# RP2350 register map
Vendor: Raspberry Pi; Series: RP; File version: 0.1
CPU: CM33 r1p0, little endian, MPU, FPU, DSP, VTOR, 4 interrupt priority bits, 52 interrupts, 8 SAU regions
Registers are 32-bit, read-write, reset 0x0 unless marked. A register's access mark holds for its fields unless they carry their own. Offsets are from the block's base; [hi:lo] are bit positions; {n}, {i} and the like mark numbered series.

## CORESIGHT_TRACE — Coresight block - RP specific registers
Base 0x50700000
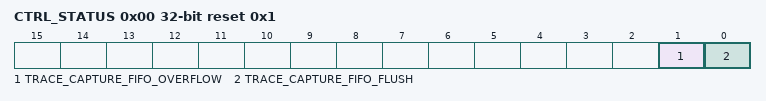
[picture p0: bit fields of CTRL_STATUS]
0x00 CTRL_STATUS reset 0x1 — Control and status register
  [1] TRACE_CAPTURE_FIFO_OVERFLOW — This status flag is set high when trace data has been dropped due to the FIFO being full at the point trace data was sampled. Write 1 to acknowledge and clear the bit.
  [0] TRACE_CAPTURE_FIFO_FLUSH — Set to 1 to continuously hold the trace FIFO in a flushed state and prevent overflow. Before clearing this flag, configure and start a DMA channel with the correct DREQ for the TRACE_CAPTURE_FIFO register. Clear this flag to begin sampling trace data, and set once again once the trace capture buffer is full. You must configure the TPIU in order to generate trace packets to be captured, as well as components like the ETM further upstream to generate the event stream propagated to the TPIU.
0x04 TRACE_CAPTURE_FIFO — FIFO for trace data captured from the TPIU
  [31:0] RDATA ro read-modifies — Read from an 8 x 32-bit FIFO containing trace data captured from the TPIU. Hardware pushes to the FIFO on rising edges of clk_sys, when either of the following is true: * TPIU TRACECTL output is low (normal trace data) * TPIU TRACETCL output is high, and TPIU TRACEDATA0 and TRACEDATA1 are both low (trigger packet) These conditions are in accordance with Arm Coresight Architecture Spec v3.0 section D3.3.3: Decoding requirements for Trace Capture Devices The data captured into the FIFO is the full 32-bit TRACEDATA bus output by the TPIU. Note that the TPIU is a DDR output at half of clk_sys, therefore this interface can capture the full 32-bit TPIU DDR output bandwidth as it samples once per active edge of the TPIU output clock.

## GLITCH_DETECTOR — Glitch detector controls
Base 0x40158000
0x00 ARM reset 0x5BAD — Forcibly arm the glitch detectors, if they are not already armed by OTP. When armed, any individual detector trigger will cause a restart of the switched core power domain's power-on reset state machine. Glitch detector triggers are recorded accumulatively in TRIG_STATUS. If the system is reset by a glitch detector trigger, this is recorded in POWMAN_CHIP_RESET. This register is Secure read/write only.
  [15:0] ARM
    0x5BAD=no (Do not force the glitch detectors to be armed); 0=yes (Force the glitch detectors to be armed. (Any value other than ARM_NO counts as YES))
0x04 DISARM
  [15:0] DISARM — Forcibly disarm the glitch detectors, if they are armed by OTP. Ignored if ARM is YES. This register is Secure read/write only.
    0=no (Do not disarm the glitch detectors. (Any value other than DISARM_YES counts as NO)); 0xDCAF=yes (Disarm the glitch detectors)
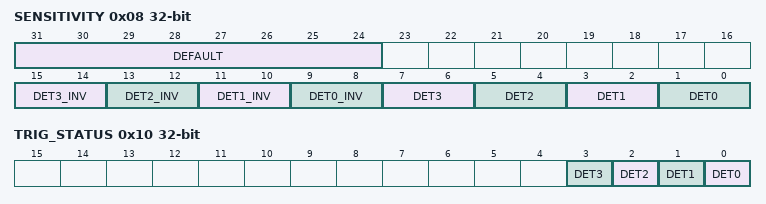
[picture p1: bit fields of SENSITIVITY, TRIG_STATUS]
0x08 SENSITIVITY — Adjust the sensitivity of glitch detectors to values other than their OTP-provided defaults. This register is Secure read/write only.
  [31:24] DEFAULT
    0=yes (Use the default sensitivity configured in OTP for all detectors. (Any value other than DEFAULT_NO counts as YES)); 222=no (Do not use the default sensitivity configured in OTP. Instead use the value from this register.)
  [2n+9:2n+8] DET{n}_INV (n=0..3) — Must be the inverse of DET{n}, else the default value is used.
  [2n+1:2n] DET{n} (n=0..3) — Set sensitivity for detector {n}. Higher values are more sensitive.
0x0C LOCK
  [7:0] LOCK — Write any nonzero value to disable writes to ARM, DISARM, SENSITIVITY and LOCK. This register is Secure read/write only.
0x10 TRIG_STATUS — Set when a detector output triggers. Write-1-clear. (May immediately return high if the detector remains in a failed state. Detectors can only be cleared by a full reset of the switched core power domain.) This register is Secure read/write only.
  [n] DET{n} write-1-clears (n=0..3)
0x14 TRIG_FORCE — Simulate the firing of one or more detectors. Writing ones to this register will set the matching bits in STATUS_TRIG. If the glitch detectors are currently armed, writing ones will also immediately reset the switched core power domain, and set the reset reason latches in POWMAN_CHIP_RESET to indicate a glitch detector resets. This register is Secure read/write only.
  [3:0] TRIG_FORCE wo

## TBMAN — For managing simulation testbenches
Base 0x40160000
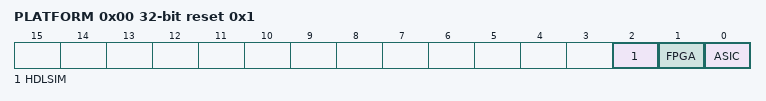
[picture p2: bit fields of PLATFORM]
0x00 PLATFORM reset 0x1 — Indicates the type of platform in use
  [2] HDLSIM ro — Indicates the platform is a simulation
  [1] FPGA ro — Indicates the platform is an FPGA
  [0] ASIC ro — Indicates the platform is an ASIC
